# D1H register map
Vendor: Allwinner; File version: 1.0
Registers are 32-bit, read-write, reset 0x0 unless marked. A register's access mark holds for its fields unless they carry their own. Offsets are from the block's base; [hi:lo] are bit positions; {n}, {i} and the like mark numbered series.

## EMAC — Ethernet Medium Access Controller
Base 0x04500000
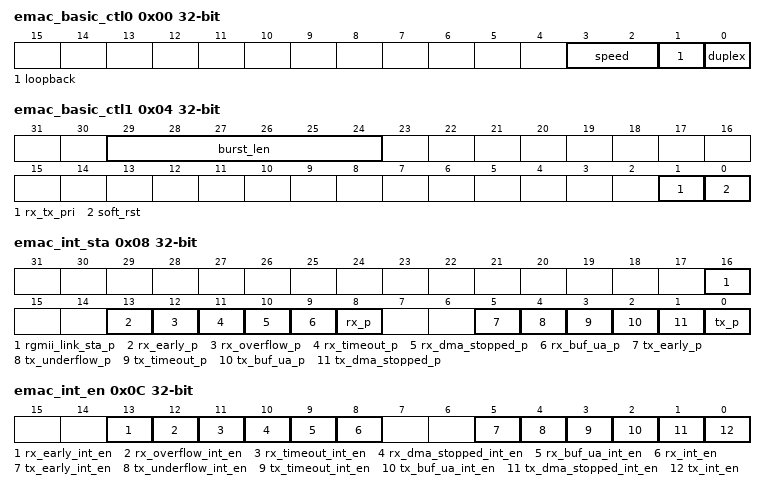
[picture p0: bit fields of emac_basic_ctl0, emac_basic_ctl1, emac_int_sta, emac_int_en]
0x00 emac_basic_ctl0 — EMAC Basic Control Register0
  [3:2] speed — EMAC Working Speed
    0=S1000; 2=S10; 3=S100
  [1] loopback — EMAC Loopback Mode For Test
    0=DISABLE; 1=ENABLE
  [0] duplex — EMAC Transfer Mode
    0=HALF_DUPLEX; 1=FULL_DUPLEX
0x04 emac_basic_ctl1 — EMAC Basic Control Register1
  [29:24] burst_len — The burst length of RX and TX DMA transfer
  [1] rx_tx_pri — RX TX DMA Priority
    0=SAME; 1=RO_T
  [0] soft_rst — Soft Reset all Registers and Logic
    0=NO_VALID; 1=RESET
0x08 emac_int_sta write-1-clears — EMAC Interrupt Status Register
  [16] rgmii_link_sta_p — RMII Link Status Changed Interrupt Pending
    0=NO_PENDING; 1=PENDING
  [13] rx_early_p — RX DMA Filled First Data Buffer of the Receive Frame Interrupt Pending
    0=NO_PENDING; 1=PENDING
  [12] rx_overflow_p — RX FIFO Overflow Error Interrupt Pending
    0=NO_PENDING; 1=PENDING
  [11] rx_timeout_p — RX Timeout Interrupt Pending
    0=NO_PENDING; 1=PENDING
  [10] rx_dma_stopped_p — When this bit asserted, the RX DMA FSM is stopped.
  [9] rx_buf_ua_p — RX Buffer UA Interrupt Pending
    0=NO_PENDING; 1=PENDING
  [8] rx_p — Frame RX Completed Interrupt Pending
    0=NO_PENDING; 1=PENDING
  [5] tx_early_p — Total interrupt pending which the frame is transmitted to FIFO
    0=NO_PENDING; 1=PENDING
  [4] tx_underflow_p — TX FIFO Underflow Interrupt Pending
    0=NO_PENDING; 1=PENDING
  [3] tx_timeout_p — Transmitter Timeout Interrupt Pending
    0=NO_PENDING; 1=PENDING
  [2] tx_buf_ua_p — TX Buffer UA Interrupt Pending
    0=NO_PENDING; 1=PENDING
  [1] tx_dma_stopped_p — Transmission DMA Stopped Interrupt Pending
    0=NO_PENDING; 1=PENDING
  [0] tx_p — Frame Transmission Interrupt Pending
    0=NO_PENDING; 1=PENDING
0x0C emac_int_en — EMAC Interrupt Enable Register
  [all] fields
    0=DISABLE; 1=ENABLE
  [13] rx_early_int_en — Early Receive Interrupt
  [12] rx_overflow_int_en — Receive Overflow Interrupt
  [11] rx_timeout_int_en — Receive Timeout Interrupt
  [10] rx_dma_stopped_int_en — Receive DMA FSM Stopped Interrupt
  [9] rx_buf_ua_int_en — Receive Buffer Unavailable Interrupt
  [8] rx_int_en — Receive Interrupt
  [5] tx_early_int_en — Early Transmit Interrupt
  [4] tx_underflow_int_en — Transmit Underflow Interrupt
  [3] tx_timeout_int_en — Transmit Timeout Interrupt
  [2] tx_buf_ua_int_en — Transmit Buffer Available Interrupt
  [1] tx_dma_stopped_int_en — Transmit DMA FSM Stopped Interrupt
  [0] tx_int_en — Transmit Interrupt
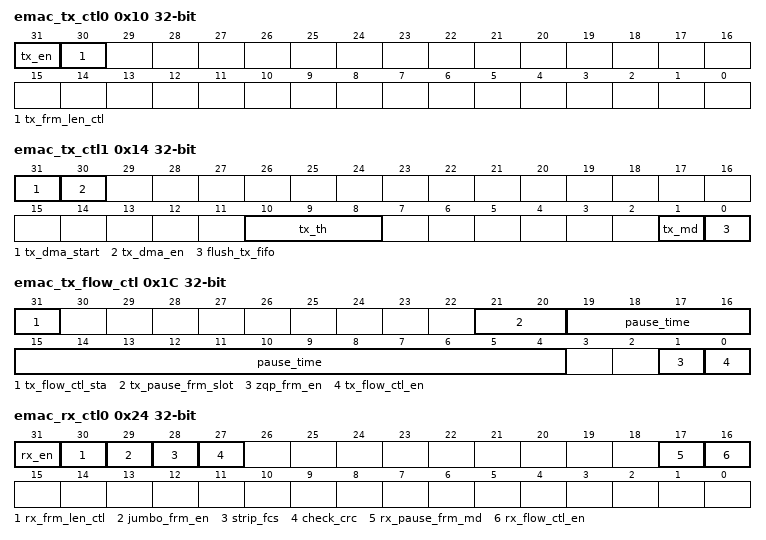
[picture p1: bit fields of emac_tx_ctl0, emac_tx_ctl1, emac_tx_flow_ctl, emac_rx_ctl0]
0x10 emac_tx_ctl0 — EMAC Transmit Control Register0
  [31] tx_en — Enable Transmitter
    0=DISABLE; 1=ENABLE
  [30] tx_frm_len_ctl — Frame Transmit Length Control
    0=B2048; 1=B16384
0x14 emac_tx_ctl1 — EMAC Transmit Control Register1
  [31] tx_dma_start — Transmit DMA FSM Start
    0=NO_VALID; 1=START
  [30] tx_dma_en — Transmit DMA Enable
    0=STOP; 1=START
  [10:8] tx_th — Threshold value of TX DMA FIFO
    0=T64; 1=T128; 2=T192; 3=T256
  [1] tx_md — Transmission Mode
    0=GREATER_THAN_TH; 1=LOCATE_FULL_FRAME
  [0] flush_tx_fifo — Flush the data in the TX FIFO
    0=ENABLE; 1=DISABLE
0x1C emac_tx_flow_ctl — EMAC Transmit Flow Control Register
  [31] tx_flow_ctl_sta
  [21:20] tx_pause_frm_slot
  [19:4] pause_time
  [1] zqp_frm_en
    0=DISABLE; 1=ENABLE
  [0] tx_flow_ctl_en — TX Flow Control Enable
    0=DISABLE; 1=ENABLE
0x20 emac_tx_dma_desc_list — EMAC Transmit Descriptor List Address Register
0x24 emac_rx_ctl0 — EMAC Receive Control Register0
  [31] rx_en — Enable Receiver
    0=DISABLE; 1=ENABLE
  [30] rx_frm_len_ctl — Frame Receive Length Control
    0=B2048; 1=B16384
  [29] jumbo_frm_en — Jumbo Frame Enable
    0=DISABLE; 1=ENABLE
  [28] strip_fcs
  [27] check_crc — Check CRC Enable
    0=DISABLE; 1=CHECK
  [17] rx_pause_frm_md
    0=ONLY_MULTICAST; 1=ALSO_UNICAST_MAC0
  [16] rx_flow_ctl_en
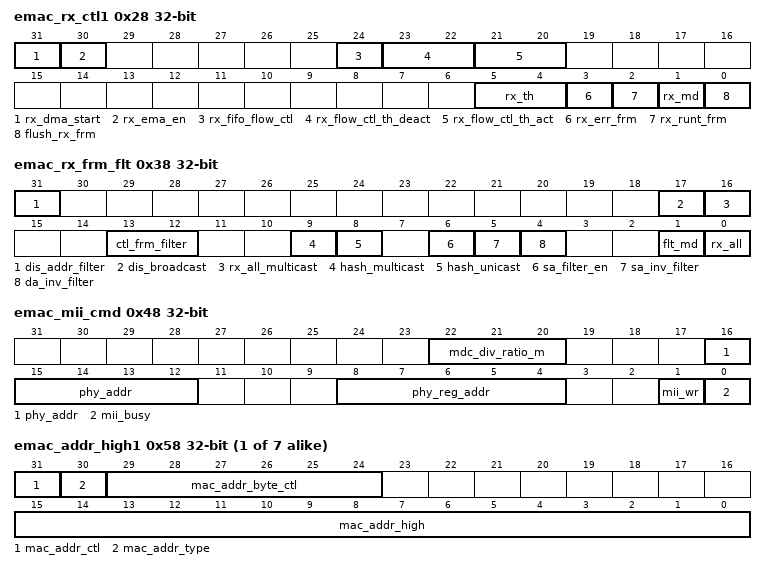
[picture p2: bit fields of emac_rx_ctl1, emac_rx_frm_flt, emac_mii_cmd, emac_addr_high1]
0x28 emac_rx_ctl1 — EMAC Receive Control Register1
  [31] rx_dma_start
  [30] rx_ema_en — Receive DMA Enable
    0=STOP; 1=START
  [24] rx_fifo_flow_ctl — Receive FIFO Flow Control Enable
    0=DISABLE; 1=ENABLE
  [23:22] rx_flow_ctl_th_deact — Threshold for Deactivating Flow Control
    {v}=FM{v+1}K (v=0..3)
  [21:20] rx_flow_ctl_th_act — Threshold for Activating Flow Control
    {v}=FM{v+1}K (v=0..3)
  [5:4] rx_th — Threshold for RX DMA FIFO Start
    0=T64; 1=T32; 2=T96; 3=T128
  [3] rx_err_frm
    0=DROP; 1=FORWARD
  [2] rx_runt_frm
  [1] rx_md — Receive Mode
    0=GREATER_THAN_TH; 1=LOCATE_FULL_FRAME
  [0] flush_rx_frm — Flush Receive Frames
    0=ENABLE; 1=DISABLE
0x34 emac_rx_dma_desc_list — EMAC Receive Descriptor List Address Register
0x38 emac_rx_frm_flt — EMAC Receive Frame Filter Register
  [31] dis_addr_filter — Disable Address Filter
    0=ENABLE; 1=DISABLE
  [17] dis_broadcast — Disable Receive Broadcast Frames
    0=RECEIVE; 1=DROP
  [16] rx_all_multicast — Receive All Multicast Frames Filter
    0=FILTER; 1=RECEIVE_ALL
  [13:12] ctl_frm_filter — Receive Control Frames Filter
    0=DROP_ALL; 2=RECEIVE_ALL; 3=RECEIVE_ALL_WHEN_FILTER
  [9] hash_multicast — Filter Multicast Frames Set
    0=DA_FIELD; 1=HASH_TABLE
  [8] hash_unicast — Filter Unicast Frames Set
    0=DA_FIELD; 1=HASH_TABLE
  [6] sa_filter_en — Receive SA Filter Enable
    0=RECEIVE_UPDATE; 1=UPDATE_DROP_UNMATCHED
  [5] sa_inv_filter — Receive SA Invert Filter Set
    0=MATCHED; 1=UNMATCHED
  [4] da_inv_filter
    0=NORMAL; 1=INVERSE_CMP_DA
  [1] flt_md
    0=PASSED_WHEN_MATCHED; 1=RECEIVE_WHEN_PASSED
  [0] rx_all — Receive All Frame
    0=RECEIVE_WHEN_PASSED; 1=RECEIVE_ALL_UPDATE
0x40 emac_rx_hash0 — EMAC Hash Table Register0
0x44 emac_rx_hash1 — EMAC Hash Table Register1
0x48 emac_mii_cmd — EMAC Management Interface Command Register
  [22:20] mdc_div_ratio_m — MDC Clock DIvider Ratio
    0=R16; 1=R32; 2=R64; 3=R128
  [16:12] phy_addr — PHY Address
  [8:4] phy_reg_addr — PHY Register Address
  [1] mii_wr — MII Write and Read
    0=R; 1=W
  [0] mii_busy — MII Status
0x4C emac_mii_data — EMAC Management Interface Data Register
  [15:0] mii_data
0x50 emac_addr_high0 — EMAC MAC Address High Register
  [15:0] mac_addr_high0
{0x54+8i} emac_addr_low{i} (i=0..7) — EMAC MAC Address Low Register
{0x50+8i} emac_addr_high{i} (i=1..7) — EMAC MAC Address High Register
  [31] mac_addr_ctl — MAC Address Valid
    0=INVALID; 1=VALID
  [30] mac_addr_type — MAC Address Type
    0=DST; 1=SRC
  [29:24] mac_addr_byte_ctl — MAC Address Byte Control Mask
  [15:0] mac_addr_high
0xB0 emac_tx_dma_sta ro — EMAC Transmit DMA Status Register
  [2:0] tx_dma_sta — The State of Transmit DMA FSM
    0=STOP; 1=RUN_FETCH_DESC; 2=RUN_WAIT_STA; 3=RUN_TRANS_DATA; 6=SUSPEND; 7=RUN_CLOSE_DESC
0xB4 emac_tx_cur_desc ro — EMAC Current Transmit Descriptor Register
0xB8 emac_tx_cur_buf ro — EMAC Current Transmit Buffer Address Register
0xC0 emac_rx_dma_sta ro — EMAC Receive DMA Status Register
  [2:0] rx_dma_sta — The State of RX DMA FSM
    0=STOP; 1=RUN_FETCH_DESC; 3=RUN_WAIT_FRM; 4=SUSPEND; 5=RUN_CLOSE_DESC; 7=RUN_TRANS_DATA
0xC4 emac_rx_cur_desc ro — EMAC Current Receive Descriptor Register
0xC8 emac_rx_cur_buf ro — EMAC Current Receive Buffer Address Register
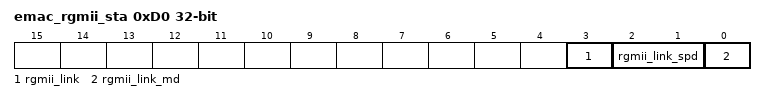
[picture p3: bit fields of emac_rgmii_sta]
0xD0 emac_rgmii_sta — EMAC RGMII Status Register
  [3] rgmii_link — The link status of the RGMII interface
    0=DOWN; 1=UP
  [2:1] rgmii_link_spd — The link speed of the RGMII interface
    0=S2_5; 1=S25; 2=S125
  [0] rgmii_link_md — The link mode of the RGMII interface
    0=HALF_DUPLEX; 1=FULL_DUPLEX
